VERSION ""

NS_ :

BS_:

BU_: IMU_CANopen_Node8

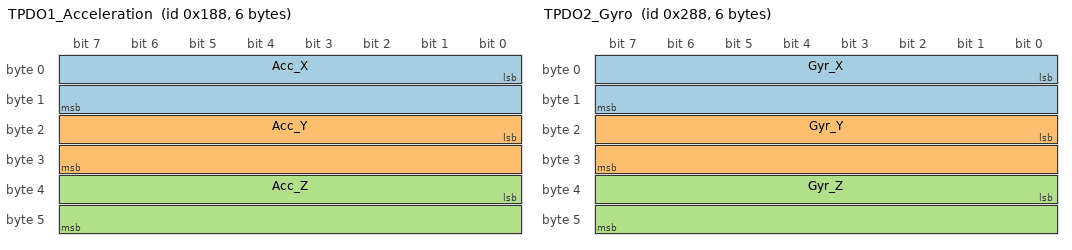
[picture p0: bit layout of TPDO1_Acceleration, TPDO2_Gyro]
BO_ 392 TPDO1_Acceleration: 6 IMU_CANopen_Node8
 SG_ Acc_X : 0|16@1- (0.001,0) [0|0] "G" Vector__XXX
 SG_ Acc_Y : 16|16@1- (0.001,0) [0|0] "G" Vector__XXX
 SG_ Acc_Z : 32|16@1- (0.001,0) [0|0] "G" Vector__XXX

BO_ 648 TPDO2_Gyro: 6 IMU_CANopen_Node8
 SG_ Gyr_X : 0|16@1- (0.1,0) [0|0] "deg/s" Vector__XXX
 SG_ Gyr_Y : 16|16@1- (0.1,0) [0|0] "deg/s" Vector__XXX
 SG_ Gyr_Z : 32|16@1- (0.1,0) [0|0] "deg/s" Vector__XXX

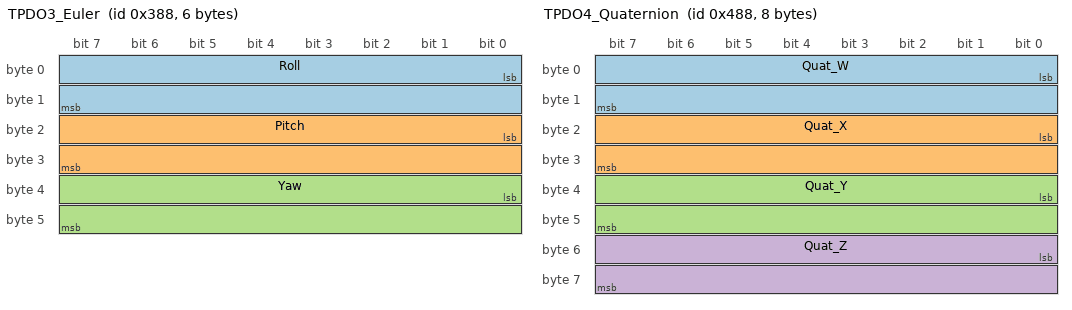
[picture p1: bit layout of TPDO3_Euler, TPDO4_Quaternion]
BO_ 904 TPDO3_Euler: 6 IMU_CANopen_Node8
 SG_ Roll : 0|16@1- (0.01,0) [0|0] "deg" Vector__XXX
 SG_ Pitch : 16|16@1- (0.01,0) [0|0] "deg" Vector__XXX
 SG_ Yaw : 32|16@1- (0.01,0) [0|0] "deg" Vector__XXX

BO_ 1160 TPDO4_Quaternion: 8 IMU_CANopen_Node8
 SG_ Quat_W : 0|16@1- (0.0001,0) [-1|1] "" Vector__XXX
 SG_ Quat_X : 16|16@1- (0.0001,0) [-1|1] "" Vector__XXX
 SG_ Quat_Y : 32|16@1- (0.0001,0) [-1|1] "" Vector__XXX
 SG_ Quat_Z : 48|16@1- (0.0001,0) [-1|1] "" Vector__XXX

BO_ 1672 TPDO6_Pressure: 4 IMU_CANopen_Node8
 SG_ Pressure : 0|32@1- (1,0) [0|0] "Pa" Vector__XXX

BO_ 1928 TPDO7_Inclinometer: 8 IMU_CANopen_Node8
 SG_ Incli_X : 0|32@1- (0.01,0) [0|0] "deg" Vector__XXX
 SG_ Incli_Y : 32|32@1- (0.01,0) [0|0] "deg" Vector__XXX

BA_DEF_  "BusType" STRING ;
BA_DEF_DEF_  "BusType" "CAN";
